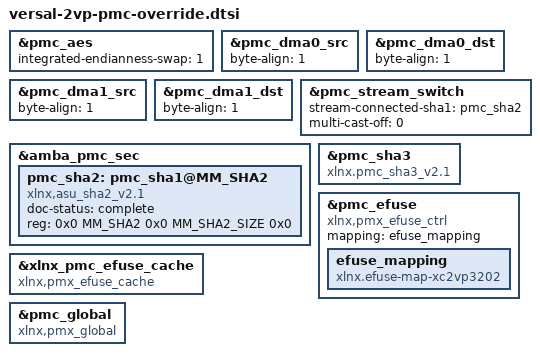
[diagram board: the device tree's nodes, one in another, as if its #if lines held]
/*
 * versal-2vp PMC configuration overrides
 *
 * Copyright (c) 2026, Advanced Micro Devices Inc.
 *
 * SPDX-License-Identifier: BSD-3-Clause
 */

/*
 * Both xc2vp3202 and xc2vp3602 have a PMXC AES with integrated endianness swap.
 */
&pmc_aes {
    integrated-endianness-swap = <1>;
};


/*
 * Only xc2vp3202 has PMXC parts.
 */
#ifndef XC2VP3602
&pmc_dma0_src {
	byte-align = <1>;
};

&pmc_dma0_dst {
	byte-align = <1>;
};

&pmc_dma1_src {
	byte-align = <1>;
};

&pmc_dma1_dst {
	byte-align = <1>;
};

&pmc_stream_switch {
#ifdef MM_SHA2
	stream-connected-sha1 = <&pmc_sha2>;
#endif
	multi-cast-off = <0>;
};

#ifdef MM_SHA2
&amba_pmc_sec {
	pmc_sha2: pmc_sha1@MM_SHA2 {
		doc-status = "complete";
		compatible = "xlnx,asu_sha2_v2.1";
		reg = <0x0 MM_SHA2 0x0 MM_SHA2_SIZE 0x0>;
	};
};
#endif

&pmc_sha3 {
	compatible = "xlnx.pmc_sha3_v2.1";
};

&pmc_efuse {
	compatible = "xlnx,pmx_efuse_ctrl";
	mapping = <&efuse_mapping>;
	efuse_mapping: efuse_mapping {
		compatible = "xlnx.efuse-map-xc2vp3202";
	};
};

&xlnx_pmc_efuse_cache {
	compatible = "xlnx,pmx_efuse_cache";
};

&pmc_global {
	compatible = "xlnx,pmx_global";
};

#endif
